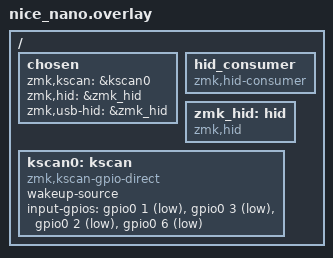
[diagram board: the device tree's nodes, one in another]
/*
 * Copyright (c) 2022 The ZMK Contributors
 *
 * SPDX-License-Identifier: MIT
 */

/ {
    chosen {
        zmk,kscan = &kscan0;
        zmk,hid = &zmk_hid;
        zmk,usb-hid = &zmk_hid;
    };

    hid_consumer {
        compatible = "zmk,hid-consumer";
    };

    zmk_hid: hid {
        compatible = "zmk,hid";
    };

    kscan0: kscan {
        compatible = "zmk,kscan-gpio-direct";
        wakeup-source;

        input-gpios
            = <&gpio0 1  (GPIO_ACTIVE_LOW | GPIO_PULL_UP)>
            , <&gpio0 3  (GPIO_ACTIVE_LOW | GPIO_PULL_UP)>
            , <&gpio0 2  (GPIO_ACTIVE_LOW | GPIO_PULL_UP)>
            , <&gpio0 6  (GPIO_ACTIVE_LOW | GPIO_PULL_UP)>
            ;
    };
};
